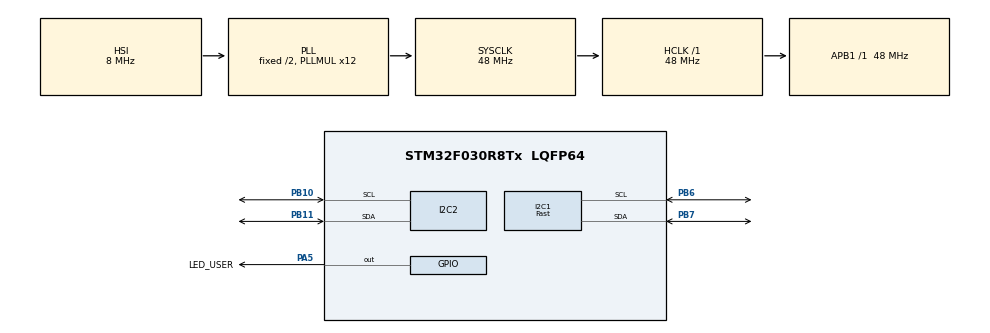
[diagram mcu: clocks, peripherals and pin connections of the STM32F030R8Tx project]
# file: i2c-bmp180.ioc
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Dma.I2C1_TX.0.Direction=DMA_MEMORY_TO_PERIPH
Dma.I2C1_TX.0.Instance=DMA1_Channel2
Dma.I2C1_TX.0.MemDataAlignment=DMA_MDATAALIGN_BYTE
Dma.I2C1_TX.0.MemInc=DMA_MINC_ENABLE
Dma.I2C1_TX.0.Mode=DMA_NORMAL
Dma.I2C1_TX.0.PeriphDataAlignment=DMA_PDATAALIGN_BYTE
Dma.I2C1_TX.0.PeriphInc=DMA_PINC_DISABLE
Dma.I2C1_TX.0.Priority=DMA_PRIORITY_LOW
Dma.I2C2_TX.1.Direction=DMA_MEMORY_TO_PERIPH
Dma.I2C2_TX.1.Instance=DMA1_Channel4
Dma.I2C2_TX.1.MemDataAlignment=DMA_MDATAALIGN_BYTE
Dma.I2C2_TX.1.MemInc=DMA_MINC_ENABLE
Dma.I2C2_TX.1.Mode=DMA_NORMAL
Dma.I2C2_TX.1.PeriphDataAlignment=DMA_PDATAALIGN_BYTE
Dma.I2C2_TX.1.PeriphInc=DMA_PINC_DISABLE
Dma.I2C2_TX.1.Priority=DMA_PRIORITY_LOW
Dma.Request0=I2C1_TX
Dma.Request1=I2C2_TX
I2C1.I2C_Speed_Mode=I2C_Fast
I2C1.OwnAddress=0
I2C1.Timing=0x0000020B
I2C2.Timing=0x20303E5D
Mcu.Family=STM32F0
Mcu.Name=STM32F030R8Tx
Mcu.Package=LQFP64
NVIC.DMA1_Channel2_3_IRQn=true\:0\:0\:false\:false\:true\:false\:true\:true
NVIC.DMA1_Channel4_5_IRQn=true\:0\:0\:false\:false\:true\:false\:true\:true
NVIC.I2C1_IRQn=true\:0\:0\:false\:false\:true\:true\:true\:true
NVIC.I2C2_IRQn=true\:0\:0\:false\:false\:true\:true\:true\:true
NVIC.RCC_IRQn=true\:0\:0\:false\:false\:true\:true\:false\:true
PA13.Mode=Serial_Wire
PA13.Signal=SYS_SWDIO
PA14.Mode=Serial_Wire
PA14.Signal=SYS_SWCLK
PA5.GPIO_Label=LED_USER
PA5.Signal=GPIO_Output
PB10.Mode=I2C
PB10.Signal=I2C2_SCL
PB11.Mode=I2C
PB11.Signal=I2C2_SDA
PB6.Mode=I2C
PB6.Signal=I2C1_SCL
PB7.Mode=I2C
PB7.Signal=I2C1_SDA
ProjectManager.HeapSize=0x200
ProjectManager.StackSize=0x400
ProjectManager.TargetToolchain=Makefile
RCC.AHBFreq_Value=48000000
RCC.APB1Freq_Value=48000000
RCC.APB1TimFreq_Value=48000000
RCC.HCLKFreq_Value=48000000
RCC.PLLMUL=RCC_PLL_MUL12
RCC.SYSCLKFreq_VALUE=48000000
RCC.SYSCLKSource=RCC_SYSCLKSOURCE_PLLCLK
board=custom

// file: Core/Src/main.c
/* USER CODE BEGIN Header */
/**
  ******************************************************************************
  * @file           : main.c
  * @brief          : Main program body
  ******************************************************************************
  * @attention
  *
  * Copyright (c) 2023 STMicroelectronics.
  * All rights reserved.
  *
  * This software is licensed under terms that can be found in the LICENSE file
  * in the root directory of this software component.
  * If no LICENSE file comes with this software, it is provided AS-IS.
  *
  ******************************************************************************
  */
/* USER CODE END Header */
#include "main.h"
#include "dma.h"
#include "i2c.h"
#include "gpio.h"

/* USER CODE BEGIN PD */
/// Semihosting Initializing.
extern void initialise_monitor_handles( void );
/* USER CODE END PD */

void SystemClock_Config(void);

int main(void)
{

  /* USER CODE BEGIN 1 */
  // �?нициализация библиотеки Semihosting.
  initialise_monitor_handles();
  /* USER CODE END 1 */

  /* MCU Configuration--------------------------------------------------------*/

  /* Reset of all peripherals, Initializes the Flash interface and the Systick. */
  HAL_Init();

  /* USER CODE BEGIN Init */
  init();
  /* USER CODE END Init */

  /* Configure the system clock */
  SystemClock_Config();

  /* Initialize all configured peripherals */
  MX_GPIO_Init();
  MX_DMA_Init();
  MX_I2C1_Init();
  MX_I2C2_Init();

  /* Infinite loop */
  /* USER CODE BEGIN WHILE */
  setup();

  while (1)
  {
    loop();

    /* USER CODE END WHILE */

  }
}

void SystemClock_Config(void)
{
  RCC_OscInitTypeDef RCC_OscInitStruct = {0};
  RCC_ClkInitTypeDef RCC_ClkInitStruct = {0};
  RCC_PeriphCLKInitTypeDef PeriphClkInit = {0};

  /** Initializes the RCC Oscillators according to the specified parameters
  * in the RCC_OscInitTypeDef structure.
  */
  RCC_OscInitStruct.OscillatorType = RCC_OSCILLATORTYPE_HSI;
  RCC_OscInitStruct.HSIState = RCC_HSI_ON;
  RCC_OscInitStruct.HSICalibrationValue = RCC_HSICALIBRATION_DEFAULT;
  RCC_OscInitStruct.PLL.PLLState = RCC_PLL_ON;
  RCC_OscInitStruct.PLL.PLLSource = RCC_PLLSOURCE_HSI;
  RCC_OscInitStruct.PLL.PLLMUL = RCC_PLL_MUL12;
  RCC_OscInitStruct.PLL.PREDIV = RCC_PREDIV_DIV1;
  if (HAL_RCC_OscConfig(&RCC_OscInitStruct) != HAL_OK)
  {
    Error_Handler();
  }

  /** Initializes the CPU, AHB and APB buses clocks
  */
  RCC_ClkInitStruct.ClockType = RCC_CLOCKTYPE_HCLK|RCC_CLOCKTYPE_SYSCLK
                              |RCC_CLOCKTYPE_PCLK1;
  RCC_ClkInitStruct.SYSCLKSource = RCC_SYSCLKSOURCE_PLLCLK;
  RCC_ClkInitStruct.AHBCLKDivider = RCC_SYSCLK_DIV1;
  RCC_ClkInitStruct.APB1CLKDivider = RCC_HCLK_DIV1;

  if (HAL_RCC_ClockConfig(&RCC_ClkInitStruct, FLASH_LATENCY_1) != HAL_OK)
  {
    Error_Handler();
  }
  PeriphClkInit.PeriphClockSelection = RCC_PERIPHCLK_I2C1;
  PeriphClkInit.I2c1ClockSelection = RCC_I2C1CLKSOURCE_HSI;
  if (HAL_RCCEx_PeriphCLKConfig(&PeriphClkInit) != HAL_OK)
  {
    Error_Handler();
  }
}

void Error_Handler(void)
{
  __disable_irq();
  while (1)
  {
  }
}
